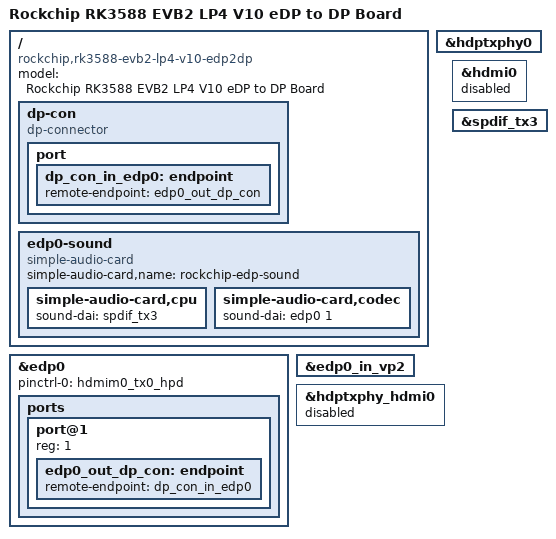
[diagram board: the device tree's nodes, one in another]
// SPDX-License-Identifier: (GPL-2.0+ OR MIT)
// Copyright (c) 2021 Rockchip Electronics Co., Ltd.

/dts-v1/;

#include "rk3588-evb2-lp4.dtsi"
#include "rk3588-android.dtsi"

/ {
	model = "Rockchip RK3588 EVB2 LP4 V10 eDP to DP Board";
	compatible = "rockchip,rk3588-evb2-lp4-v10-edp2dp", "rockchip,rk3588";

	dp-con {
		compatible = "dp-connector";
		status = "okay";

		port {
			dp_con_in_edp0: endpoint {
				remote-endpoint = <&edp0_out_dp_con>;
			};
		};
	};

	edp0-sound {
		compatible = "simple-audio-card";
		simple-audio-card,name = "rockchip-edp-sound";

		simple-audio-card,cpu {
			sound-dai = <&spdif_tx3>;
		};

		simple-audio-card,codec {
			sound-dai = <&edp0 1>;
		};
	};
};

&edp0 {
	pinctrl-names = "default";
	pinctrl-0 = <&hdmim0_tx0_hpd>;
	#sound-dai-cells = <1>;
	status = "okay";

	ports {
		port@1 {
			reg = <1>;

			edp0_out_dp_con: endpoint {
				remote-endpoint = <&dp_con_in_edp0>;
			};
		};
	};
};

&edp0_in_vp2 {
	status = "okay";
};

&hdptxphy0 {
	status = "okay";
};

&hdptxphy_hdmi0 {
	status = "disabled";
};

&hdmi0 {
	status = "disabled";
};

&spdif_tx3 {
	status = "okay";
};
